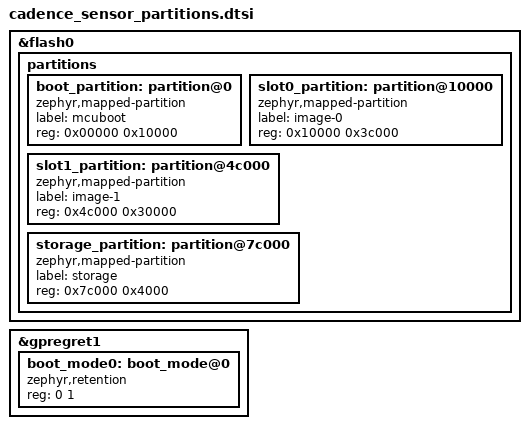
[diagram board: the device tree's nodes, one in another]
/* Stable OTA layout: slot1 is a resident Loader, never a staging slot. */
&flash0 {
	partitions {
		ranges;
		#address-cells = <1>;
		#size-cells = <1>;
		boot_partition: partition@0 {
			compatible = "zephyr,mapped-partition";
			label = "mcuboot";
			reg = <0x00000 0x10000>;
		};
		slot0_partition: partition@10000 {
			compatible = "zephyr,mapped-partition";
			label = "image-0";
			reg = <0x10000 0x3c000>;
		};
		slot1_partition: partition@4c000 {
			compatible = "zephyr,mapped-partition";
			label = "image-1";
			reg = <0x4c000 0x30000>;
		};
		storage_partition: partition@7c000 {
			compatible = "zephyr,mapped-partition";
			label = "storage";
			reg = <0x7c000 0x4000>;
		};
	};
};

&gpregret1 {
	status = "okay";
	boot_mode0: boot_mode@0 {
		compatible = "zephyr,retention";
		status = "okay";
		reg = <0 1>;
	};
};
